# AST1060 register map
File version: 1.0
CPU: CM4 r0p1, little endian, MPU, FPU, 4 interrupt priority bits, 256 interrupts
Registers are 32-bit, read-write, reset 0x0 unless marked. A register's access mark holds for its fields unless they carry their own. Offsets are from the block's base; [hi:lo] are bit positions.

## hace
Base 0x7E6D0000
0x00 HACE00 (reset mask 0x7FFFFFF8) — Crypto Data Source Base Address Register
  [30:3] BaseAddrOfSgListForCryptoSrcData303 — Base address of scatter-gather list for crypto source data[30:3] (8-byte aligned)
  [30:0] BaseAddrOfCryptoSrcData300 — Base address of crypto source data[30:0] (byte aligned)
0x04 HACE04 (reset mask 0x7FFFFFF8) — Crypto Data Destination Base Address Register
  [30:3] BaseAddrOfSgListForCryptoDestData303 — Base address of scatter-gather list for crypto destination data[30:3] (8-byte aligned)
  [30:0] BaseAddrOfCryptoDestData300 — Base address of crypto destination data[30:0] (byte aligned)
0x08 HACE08 — Crypto Context Buffer Base Address Registerr
  [30:3] BaseAddrOfCryptoCtxBuf303 — Base address of crypto context buffer[30:3] (8-byte aligned)
0x0C HACE0C — Crypto Data Length Register
  [27:0] CryptoDataLenBytes — Crypto data length (bytes)
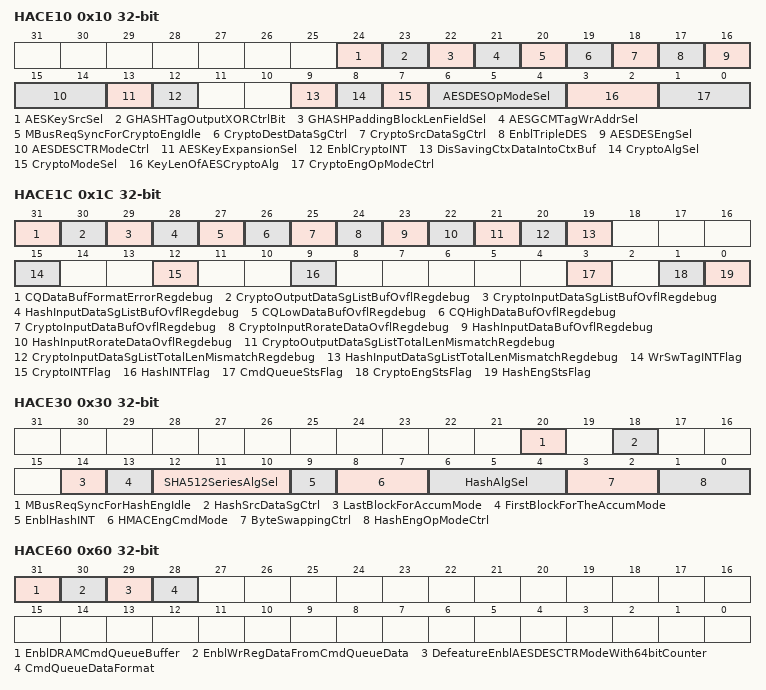
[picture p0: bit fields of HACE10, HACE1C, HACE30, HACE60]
0x10 HACE10 (reset mask 0x113D3FF) — Crypto Engine Command Register
  [24] AESKeySrcSel — AES Key source selection
  [23] GHASHTagOutputXORCtrlBit — GHASH Tag output XOR control bit
  [22] GHASHPaddingBlockLenFieldSel — GHASH padding block length field selection
  [21] AESGCMTagWrAddrSel — AES-GCM Tag write address selection
  [20] MBusReqSyncForCryptoEngIdle — M-Bus request synchronization for Crypto Engine Idle
  [19] CryptoDestDataSgCtrl — Crypto destination data scatter-gather control
  [18] CryptoSrcDataSgCtrl — Crypto source data scatter-gather control
  [17] EnblTripleDES — Enable triple DES
  [16] AESDESEngSel — AES/DES engine selection
  [15:14] AESDESCTRModeCtrl — AES/DES CTR mode control
  [13] AESKeyExpansionSel — AES key expansion selection
  [12] EnblCryptoINT — Enable crypto interrupt
  [9] DisSavingCtxDataIntoCtxBuf — Disable saving context data into context buffer
  [8] CryptoAlgSel — Crypto algorithm selection
  [7] CryptoModeSel — Crypto mode selection
  [6:4] AESDESOpModeSel — AES/DES operation mode selection
  [3:2] KeyLenOfAESCryptoAlg — Key length of AES crypto algorithm
  [1:0] CryptoEngOpModeCtrl — Crypto engine operation mode control
0x14 HACE14 — Crypto AES-GCM Additional Data Length Register
  [27:0] CryptoAESGCMAddDataLenBytes — Crypto AES-GCM additional data length (bytes)
0x18 HACE18 — Crypto AES-GCM Tag Write Buffer Base Address Register
  [30:0] BaseAddrOfCryptoAESGCMTagWrBuf300 — Base address of crypto AES-GCM Tag write buffer[30:0] (byte aligned)
0x1C HACE1C — HAC Engine Status Register
  [31] CQDataBufFormatErrorRegdebug ro — CQ data buffer format error regdebug
  [30] CryptoOutputDataSgListBufOvflRegdebug ro — Crypto output data scatter and gather list buffer overflow regdebug
  [29] CryptoInputDataSgListBufOvflRegdebug ro — Crypto input data scatter and gather list buffer overflow regdebug
  [28] HashInputDataSgListBufOvflRegdebug ro — Hash input data scatter and gather list buffer overflow regdebug
  [27] CQLowDataBufOvflRegdebug ro — CQ low data buffer overflow regdebug
  [26] CQHighDataBufOvflRegdebug ro — CQ high data buffer overflow regdebug
  [25] CryptoInputDataBufOvflRegdebug ro — Crypto input data buffer overflow regdebug
  [24] CryptoInputRorateDataOvflRegdebug ro — Crypto input rorate data overflow regdebug
  [23] HashInputDataBufOvflRegdebug ro — Hash input data buffer overflow regdebug
  [22] HashInputRorateDataOvflRegdebug ro — Hash input rorate data overflow regdebug
  [21] CryptoOutputDataSgListTotalLenMismatchRegdebug ro — Crypto output data scatter and gather list total length mismatch regdebug
  [20] CryptoInputDataSgListTotalLenMismatchRegdebug ro — Crypto input data scatter and gather list total length mismatch regdebug
  [19] HashInputDataSgListTotalLenMismatchRegdebug ro — Hash input data scatter and gather list total length mismatch regdebug
  [15] WrSwTagINTFlag — Write software tag interrupt flag
  [12] CryptoINTFlag — Crypto interrupt flag
  [9] HashINTFlag — Hash interrupt flag
  [3] CmdQueueStsFlag ro — Command queue status flag
  [1] CryptoEngStsFlag ro — Crypto engine status flag
  [0] HashEngStsFlag ro — Hash engine status flag
0x20 HACE20 (reset mask 0x7FFFFFF8) — Hash Data Source Base Address Register
  [30:3] BaseAddrOfSgListForHashSrcData303 — Base address of scatter-gather list for hash source data[30:3] (8-byte aligned)
  [30:0] BaseAddrOfHashSrcData300 — Base address of hash source data[30:0] (byte aligned)
0x24 HACE24 — Hash Digest Write Buffer Base Address Register
  [30:3] BaseAddrOfHashDigestWrBuf303 — Base address of hash digest write buffer[30:3] (8-byte aligned)
0x28 HACE28 — Hash HMAC Key Buffer Base Address Register
  [30:3] BaseAddrOfHMACKeyBuf302 — Base address of HMAC key buffer[30:2] (8-byte aligned)
0x2C HACE2C — Hash Data Length Register
  [27:0] HashDataLen — Hash data length
0x30 HACE30 (reset mask 0x101FFF) — Hash Engine Command Register
  [20] MBusReqSyncForHashEngIdle — M-Bus request synchronization for Hash Engine Idle
  [18] HashSrcDataSgCtrl — Hash source data scatter-gather control
  [14] LastBlockForAccumMode — Last block for accumulative mode
  [13] FirstBlockForTheAccumMode — First block for the accumulative mode
  [12:10] SHA512SeriesAlgSel — SHA-512 series algorithm selection
  [9] EnblHashINT — Enable hash interrupt
  [8:7] HMACEngCmdMode — HMAC engine command mode
  [6:4] HashAlgSel — Hash algorithm selection
  [3:2] ByteSwappingCtrl — Byte swapping control
  [1:0] HashEngOpModeCtrl — Hash engine operation mode control
0x34 HACE34 — Hash Data Padding Length Register
  [27:0] HashDataPaddingLen — Hash data padding length
0x50 HACE50 — Command Queue Base Address
  [30:4] CmdQueueBaseAddr304 — Command queue base address[30:4] (16-byte aligned)
0x54 HACE54 — Command Queue End Pointer
  [11:1] CmdQueueEndPointer111Bf — Command queue end pointer[11:1] bf(16-byte aligned)
0x58 HACE58 — Command Queue Write Pointer
  [11:0] CmdQueueWrPointer110 — Command queue write pointer[11:0] (8-byte aligned)
0x5C HACE5C — Command Queue Read Pointer
  [11:0] CmdQueueReadPointer110 ro — Command queue read pointer[11:0] (8-byte aligned)
0x60 HACE60 — HAC Engine Feature Register
  [31] EnblDRAMCmdQueueBuffer — Enable DRAM Command Queue Buffer
  [30] EnblWrRegDataFromCmdQueueData — Enable Write Register Data from Command Queue Data
  [29] DefeatureEnblAESDESCTRModeWith64bitCounter — defeatureEnable AES/DES CTR Mode with 64-bit Counter
  [28] CmdQueueDataFormat — Command Queue Data Format
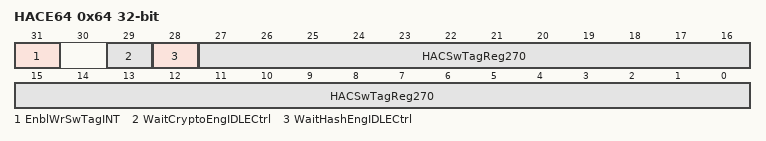
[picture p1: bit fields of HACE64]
0x64 HACE64 — HAC Software Tag Register
  [31] EnblWrSwTagINT — Enable write software tag interrupt
  [29] WaitCryptoEngIDLECtrl — Wait Crypto Engine IDLE Control
  [28] WaitHashEngIDLECtrl — Wait Hash Engine IDLE Control
  [27:0] HACSwTagReg270 — HAC software tag register[27:0]
